AUTOSAR XML (schema 4-0-3)
standard types defined: Boolean, UInt16, UInt8
package /AUTOSAR_Platform/DataConstrs
  range DC_Boolean: raw 0..1
  range DC_UInt16: raw 0..65535
package /PATAC/Facility/DataTypes/Implementation
  compu method COMPU_Boolean: 0=FALSE, 1=TRUE
  unit NoUnit: factor-si-to-unit=1, offset-si-to-unit=0
package /PATAC/MSM/ComponentTypes
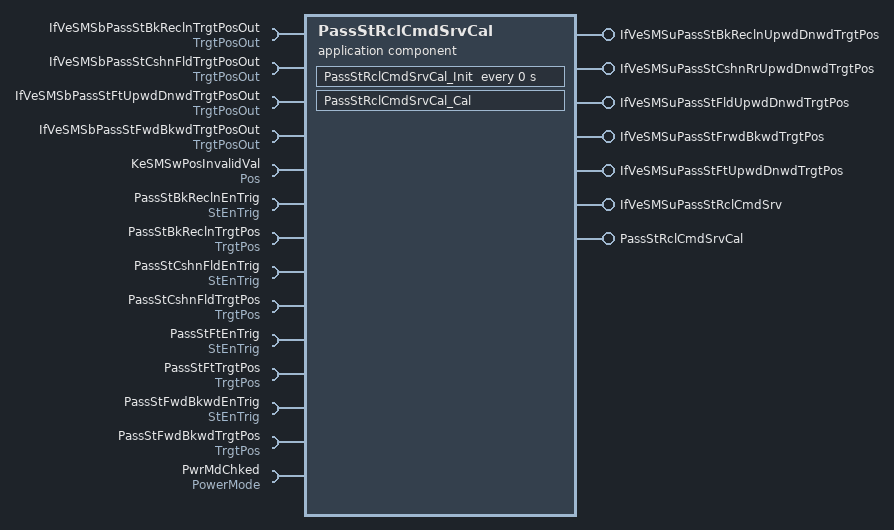
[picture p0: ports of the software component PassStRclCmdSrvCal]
  application sw component type PassStRclCmdSrvCal
    7 x provide port:
      IfVeSMSuPassStBkReclnUpwdDnwdTrgtPos: nonqueued-sender-com-spec{data-element=IfVeSMSuPassStBkReclnUpwdDnwdTrgtPos/Val, init-value=4095}, provided-interface=IfVeSMSuPassStBkReclnUpwdDnwdTrgtPos
      IfVeSMSuPassStCshnRrUpwdDnwdTrgtPos: nonqueued-sender-com-spec=data-element=IfVeSMSuPassStCshnRrUpwdDnwdTrgtPos/Val, provided-interface=IfVeSMSuPassStCshnRrUpwdDnwdTrgtPos
      IfVeSMSuPassStFldUpwdDnwdTrgtPos: nonqueued-sender-com-spec{data-element=IfVeSMSuPassStFldUpwdDnwdTrgtPos/Val, init-value=4095}, provided-interface=IfVeSMSuPassStFldUpwdDnwdTrgtPos
      IfVeSMSuPassStFrwdBkwdTrgtPos: nonqueued-sender-com-spec{data-element=IfVeSMSuPassStFrwdBkwdTrgtPos/Val, init-value=4095}, provided-interface=IfVeSMSuPassStFrwdBkwdTrgtPos
      IfVeSMSuPassStFtUpwdDnwdTrgtPos: nonqueued-sender-com-spec{data-element=IfVeSMSuPassStFtUpwdDnwdTrgtPos/Val, init-value=4095}, provided-interface=IfVeSMSuPassStFtUpwdDnwdTrgtPos
      IfVeSMSuPassStRclCmdSrv: nonqueued-sender-com-spec{data-element=IfVeSMSuPassStRclCmdSrv/Val, init-value=0}, provided-interface=IfVeSMSuPassStRclCmdSrv
      PassStRclCmdSrvCal: server-com-spec{operation=Cal, queue-length=1}, provided-interface=PassStRclCmdSrvCal
    14 x require port:
      IfVeSMSbPassStBkReclnTrgtPosOut: nonqueued-receiver-com-spec{data-element=TrgtPosOut/Val, filter=data-filter-type=ALWAYS, init-value=0}, required-interface=TrgtPosOut
      IfVeSMSbPassStCshnFldTrgtPosOut: nonqueued-receiver-com-spec{data-element=TrgtPosOut/Val, filter=data-filter-type=ALWAYS, init-value=0}, required-interface=TrgtPosOut
      IfVeSMSbPassStFtUpwdDnwdTrgtPosOut: nonqueued-receiver-com-spec{data-element=TrgtPosOut/Val, filter=data-filter-type=ALWAYS, init-value=0}, required-interface=TrgtPosOut
      IfVeSMSbPassStFwdBkwdTrgtPosOut: nonqueued-receiver-com-spec{data-element=TrgtPosOut/Val, filter=data-filter-type=ALWAYS, init-value=0}, required-interface=TrgtPosOut
      KeSMSwPosInvalidVal: parameter-require-com-spec{init-value=4095, parameter=Val}, required-interface=Pos
      PassStBkReclnEnTrig: nonqueued-receiver-com-spec{data-element=StEnTrig/Val, filter=data-filter-type=ALWAYS, init-value=0}, required-interface=StEnTrig
      PassStBkReclnTrgtPos: nonqueued-receiver-com-spec{data-element=TrgtPos/Val, filter=data-filter-type=ALWAYS, init-value=4095}, required-interface=TrgtPos
      PassStCshnFldEnTrig: nonqueued-receiver-com-spec{data-element=StEnTrig/Val, filter=data-filter-type=ALWAYS, init-value=0}, required-interface=StEnTrig
      PassStCshnFldTrgtPos: nonqueued-receiver-com-spec{data-element=TrgtPos/Val, filter=data-filter-type=ALWAYS, init-value=4095}, required-interface=TrgtPos
      PassStFtEnTrig: nonqueued-receiver-com-spec{data-element=StEnTrig/Val, filter=data-filter-type=ALWAYS, init-value=0}, required-interface=StEnTrig
      PassStFtTrgtPos: nonqueued-receiver-com-spec{data-element=TrgtPos/Val, filter=data-filter-type=ALWAYS, init-value=4095}, required-interface=TrgtPos
      PassStFwdBkwdEnTrig: nonqueued-receiver-com-spec{data-element=StEnTrig/Val, filter=data-filter-type=ALWAYS, init-value=0}, required-interface=StEnTrig
      PassStFwdBkwdTrgtPos: nonqueued-receiver-com-spec{data-element=TrgtPos/Val, filter=data-filter-type=ALWAYS, init-value=4095}, required-interface=TrgtPos
      PwrMdChked: nonqueued-receiver-com-spec{data-element=PowerMode/Val, filter=data-filter-type=ALWAYS, init-value=0}, required-interface=PowerMode
    behavior PassStRclCmdSrvCal_InternalBehavior
      operation invoked event OIT_PassStRclCmdSrvCal_Cal_PassStRclCmdSrvCal_Cal: start-on-event=PassStRclCmdSrvCal_Cal, operation=PassStRclCmdSrvCal.Cal
      timing event PassStRclCmdSrvCal_InitEvent: start-on-event=PassStRclCmdSrvCal_Init, period=0
      runnable PassStRclCmdSrvCal_Cal
        data-receive-point-by-arguments:
          13 x access:
            REC_IfVeSMSbPassStBkReclnTrgtPosOut_Val: accessed-variable=IfVeSMSbPassStBkReclnTrgtPosOut.Val
            REC_IfVeSMSbPassStCshnFldTrgtPosOut_Val: accessed-variable=IfVeSMSbPassStCshnFldTrgtPosOut.Val
            REC_IfVeSMSbPassStFtUpwdDnwdTrgtPosOut_Val: accessed-variable=IfVeSMSbPassStFtUpwdDnwdTrgtPosOut.Val
            REC_IfVeSMSbPassStFwdBkwdTrgtPosOut_Val: accessed-variable=IfVeSMSbPassStFwdBkwdTrgtPosOut.Val
            REC_PassStBkReclnEnTrig_Val: accessed-variable=PassStBkReclnEnTrig.Val
            REC_PassStBkReclnTrgtPos_Val: accessed-variable=PassStBkReclnTrgtPos.Val
            REC_PassStCshnFldEnTrig_Val: accessed-variable=PassStCshnFldEnTrig.Val
            REC_PassStCshnFldTrgtPos_Val: accessed-variable=PassStCshnFldTrgtPos.Val
            REC_PassStFtEnTrig_Val: accessed-variable=PassStFtEnTrig.Val
            REC_PassStFtTrgtPos_Val: accessed-variable=PassStFtTrgtPos.Val
            REC_PassStFwdBkwdEnTrig_Val: accessed-variable=PassStFwdBkwdEnTrig.Val
            REC_PassStFwdBkwdTrgtPos_Val: accessed-variable=PassStFwdBkwdTrgtPos.Val
            REC_PwrMdChked_Val: accessed-variable=PwrMdChked.Val
        data-send-points:
          6 x access:
            SEND_IfVeSMSuPassStBkReclnUpwdDnwdTrgtPos_Val: accessed-variable=IfVeSMSuPassStBkReclnUpwdDnwdTrgtPos.Val
            SEND_IfVeSMSuPassStCshnRrUpwdDnwdTrgtPos_Val: accessed-variable=IfVeSMSuPassStCshnRrUpwdDnwdTrgtPos.Val
            SEND_IfVeSMSuPassStFldUpwdDnwdTrgtPos_Val: accessed-variable=IfVeSMSuPassStFldUpwdDnwdTrgtPos.Val
            SEND_IfVeSMSuPassStFrwdBkwdTrgtPos_Val: accessed-variable=IfVeSMSuPassStFrwdBkwdTrgtPos.Val
            SEND_IfVeSMSuPassStFtUpwdDnwdTrgtPos_Val: accessed-variable=IfVeSMSuPassStFtUpwdDnwdTrgtPos.Val
            SEND_IfVeSMSuPassStRclCmdSrv_Val: accessed-variable=IfVeSMSuPassStRclCmdSrv.Val
        parameter access PA_KeSMSwPosInvalidVal_Val: accessed-parameter=KeSMSwPosInvalidVal.Val
      runnable PassStRclCmdSrvCal_Init
        parameter access PA_KeSMSwPosInvalidVal_Val: accessed-parameter=KeSMSwPosInvalidVal.Val
  swc implementation PassStRclCmdSrvCal_Implementation: behavior=PassStRclCmdSrvCal_InternalBehavior
    code-descriptors:
      code Default: artifact-descriptors=autosar-engineering-object={short-label=Default, category=SWSRC}
package /PATAC/MSM/ModeAdjust/CalPortInterface
  parameter interface Pos
    parameter data prototype Val: sw-calibration-access=READ-WRITE, type=UInt16
package /PATAC/MSM/ModeAdjust/DataType
  impl type PowerMode1: category=VALUE, base-type=UInt8, sw-calibration-access=READ-ONLY, compu {0=PowerMode_Off, 1=PowerMode_Acc, 2=PowerMode_Run, 3=PowerMode_Crank, 4=PowerMode_Invalid}, type-emitter=RTE
package /PATAC/MSM/ModeAdjust/Interfaces
  sender receiver interface IfVeSMSuPassStRclCmdSrv: invalidation-policy{data-element=IfVeSMSuPassStRclCmdSrv/Val, handle-invalid=DONT-INVALIDATE}
    data Val: type=Boolean
package /PATAC/MSM/ModeAdjust/PortInterface
  client server interface PassStRclCmdSrvCal
    operation Cal
  sender receiver interface PowerMode: invalidation-policy{data-element=PowerMode/Val, handle-invalid=DONT-INVALIDATE}
    data Val: type=PowerMode1
  sender receiver interface StEnTrig: invalidation-policy{data-element=StEnTrig/Val, handle-invalid=DONT-INVALIDATE}
    data Val: type=Boolean
  sender receiver interface TrgtPosOut: invalidation-policy{data-element=TrgtPosOut/Val, handle-invalid=DONT-INVALIDATE}
    data Val: type=Boolean
package /PATAC/MSM/PortInterfaces
  6 x sender receiver interface:
    IfVeSMSuPassStBkReclnUpwdDnwdTrgtPos: invalidation-policy{data-element=IfVeSMSuPassStBkReclnUpwdDnwdTrgtPos/Val, handle-invalid=DONT-INVALIDATE}
      data Val: type=UInt16
    IfVeSMSuPassStCshnRrUpwdDnwdTrgtPos: invalidation-policy{data-element=IfVeSMSuPassStCshnRrUpwdDnwdTrgtPos/Val, handle-invalid=DONT-INVALIDATE}
      data Val: type=UInt16
    IfVeSMSuPassStFldUpwdDnwdTrgtPos: invalidation-policy{data-element=IfVeSMSuPassStFldUpwdDnwdTrgtPos/Val, handle-invalid=DONT-INVALIDATE}
      data Val: type=UInt16
    IfVeSMSuPassStFrwdBkwdTrgtPos: invalidation-policy{data-element=IfVeSMSuPassStFrwdBkwdTrgtPos/Val, handle-invalid=DONT-INVALIDATE}
      data Val: type=UInt16
    IfVeSMSuPassStFtUpwdDnwdTrgtPos: invalidation-policy{data-element=IfVeSMSuPassStFtUpwdDnwdTrgtPos/Val, handle-invalid=DONT-INVALIDATE}
      data Val: type=UInt16
    TrgtPos: invalidation-policy{data-element=TrgtPos/Val, handle-invalid=DONT-INVALIDATE}
      data Val: type=UInt16
